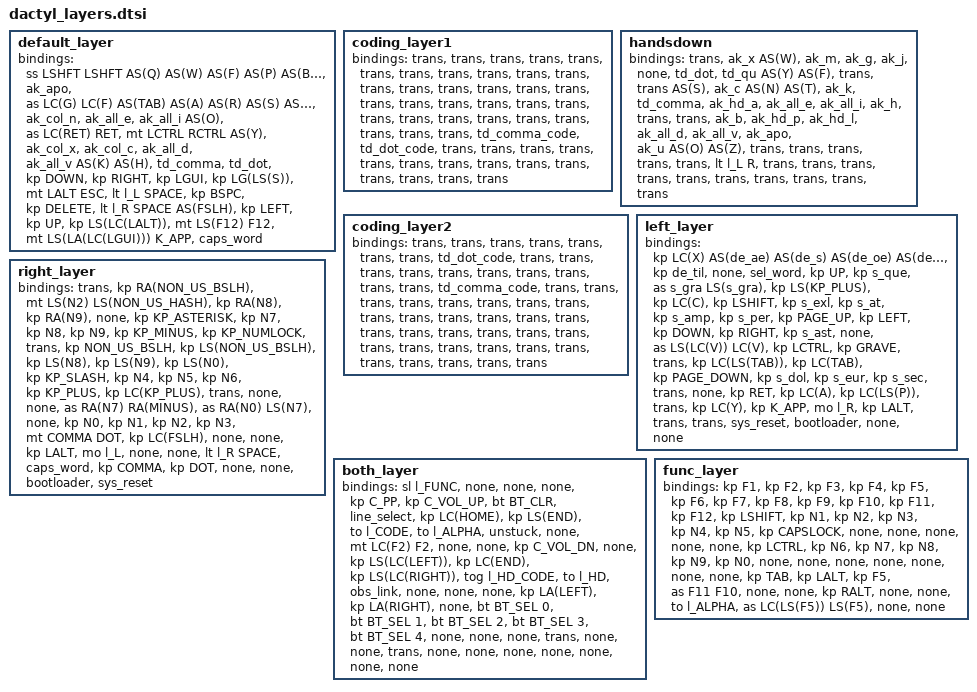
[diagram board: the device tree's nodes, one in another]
default_layer {
        bindings = <
&ss LSHFT LSHFT AS(Q) AS(W)     AS(F)     AS(P)     AS(B)                                   AS(J)  AS(L)     AS(U)      AS(Z)      &ak_apo      &as LC(G) LC(F)
AS(TAB)         AS(A) AS(R)     AS(S)     AS(T)     AS(G)                                   AS(M)  &ak_col_n &ak_all_e  &ak_all_i  AS(O)        &as LC(RET) RET
&mt LCTRL RCTRL AS(Y) &ak_col_x &ak_col_c &ak_all_d &ak_all_v                               AS(K)  AS(H)     &td_comma  &td_dot    &kp DOWN     &kp RIGHT
                &kp LGUI &kp LG(LS(S)) &mt LALT ESC &lt l_L SPACE &kp BSPC  &kp DELETE   &lt l_R SPACE   AS(FSLH)    &kp LEFT  &kp UP
                                        &kp LS(LC(LALT)) &mt LS(F12) F12         &mt LS(LA(LC(LGUI))) K_APP   &caps_word
        >;
    };

coding_layer1{
        bindings = <
&trans &trans &trans &trans &trans &trans       &trans &trans &trans         &trans &trans &trans
&trans &trans &trans &trans &trans &trans       &trans &trans &trans         &trans &trans &trans
&trans &trans &trans &trans &trans &trans       &trans &trans &td_comma_code &td_dot_code &trans &trans
       &trans &trans &trans &trans &trans       &trans &trans &trans        &trans &trans
                                        &trans &trans 
        >;

};

 handsdown {
    bindings = <    
&trans  &ak_x  AS(W)    &ak_m    &ak_g     &ak_j         &none      &td_dot  &td_qu    AS(Y)    AS(F)  &trans
&trans  AS(S)  &ak_c    AS(N)    AS(T)     &ak_k         &td_comma  &ak_hd_a &ak_all_e &ak_all_i &ak_h  &trans
&trans  &ak_b  &ak_hd_p &ak_hd_l &ak_all_d &ak_all_v     &ak_apo    &ak_u    AS(O)     AS(Z)      &trans &trans
            &trans  &trans &trans &lt l_L R &trans  &trans &trans  &trans &trans &trans
                                &trans  &trans              &trans &trans
    >;
};


coding_layer2{
        bindings = <
&trans &trans &trans &trans &trans &trans       &trans          &td_dot_code &trans &trans &trans &trans 
&trans &trans &trans &trans &trans &trans       &td_comma_code &trans  &trans &trans &trans &trans
&trans &trans &trans &trans &trans &trans       &trans          &trans  &trans &trans &trans &trans
       &trans &trans &trans &trans &trans       &trans          &trans  &trans &trans &trans
                                &trans &trans &trans &trans 
        >;

};
    left_layer {
        bindings = <
&kp LC(X)            AS(de_ae)   AS(de_s)   AS(de_oe)     AS(de_ue)       &kp de_til        &none          &sel_word   &kp UP     &kp s_que     &as s_gra LS(s_gra) &kp LS(KP_PLUS)
&kp LC(C)            &kp LSHIFT  &kp s_exl  &kp s_at      &kp s_amp       &kp s_per         &kp PAGE_UP    &kp LEFT    &kp DOWN   &kp RIGHT     &kp s_ast           &none
&as LS(LC(V)) LC(V)  &kp LCTRL   &kp GRAVE  &trans        &kp LC(LS(TAB))  &kp LC(TAB)      &kp PAGE_DOWN  &kp s_dol   &kp s_eur  &kp s_sec     &trans              &none
                    &kp RET    &kp LC(A)    &kp LC(LS(P))  &trans        &kp LC(Y)         &kp K_APP         &mo l_R     &kp LALT   &trans        &trans                                                    
                                                    &sys_reset   &bootloader                      &none       &none 
    >; 
    };

    right_layer {
        bindings = <
&trans &kp RA(NON_US_BSLH) &mt LS(N2) LS(NON_US_HASH)  &kp RA(N8)          &kp RA(N9)         &none                           &kp KP_ASTERISK &kp N7   &kp N8    &kp N9  &kp KP_MINUS   &kp KP_NUMLOCK
&trans &kp NON_US_BSLH     &kp LS(NON_US_BSLH)         &kp LS(N8)          &kp LS(N9)         &kp LS(N0)                      &kp KP_SLASH    &kp N4   &kp N5    &kp N6  &kp KP_PLUS    &kp LC(KP_PLUS)
&trans &none               &none                       &as RA(N7) RA(MINUS) &as RA(N0) LS(N7) &none                           &kp N0          &kp N1   &kp N2    &kp N3  &mt COMMA DOT  &kp LC(FSLH)
                           &none                       &none               &kp LALT              &mo l_L  &none    &none    &lt l_R SPACE  &caps_word  &kp COMMA &kp DOT
                                                                                            &none    &none             &bootloader &sys_reset
    >;
 };

    both_layer {
        bindings = <
&sl l_FUNC &none  &none         &none  &kp C_PP      &kp C_VOL_UP        &bt BT_CLR &line_select      &kp LC(HOME)  &kp LS(END)         &to l_CODE     &to l_ALPHA
&unstuck      &none  &mt LC(F2) F2 &none  &none         &kp C_VOL_DN        &none      &kp LS(LC(LEFT))  &kp LC(END)   &kp LS(LC(RIGHT))   &tog l_HD_CODE  &to l_HD
&obs_link  &none  &none     &none  &kp LA(LEFT)  &kp LA(RIGHT)       &none      &bt BT_SEL 0      &bt BT_SEL 1  &bt BT_SEL 2        &bt BT_SEL 3   &bt BT_SEL 4
                        &none   &none     &none  &trans &none           &none  &trans  &none &none  &none
                                             &none  &none        &none     &none
        >;
    };

    func_layer {
        bindings = <
&kp F1      &kp F2      &kp F3    &kp F4      &kp F5     &kp F6                              &kp F7        &kp F8  &kp F9   &kp F10  &kp F11  &kp F12
&kp LSHIFT  &kp N1      &kp N2    &kp N3      &kp N4     &kp N5                              &kp CAPSLOCK &none   &none    &none    &none    &none
&kp LCTRL   &kp N6      &kp N7    &kp N8      &kp N9     &kp N0                              &none         &none   &none    &none    &none    &none
                        &none     &kp TAB     &kp LALT   &kp F5    &as F11 F10        &none  &none     &kp RALT    &none       &none
                                                &to l_ALPHA   &as LC(LS(F5)) LS(F5)     &none   &none
        >;
    };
